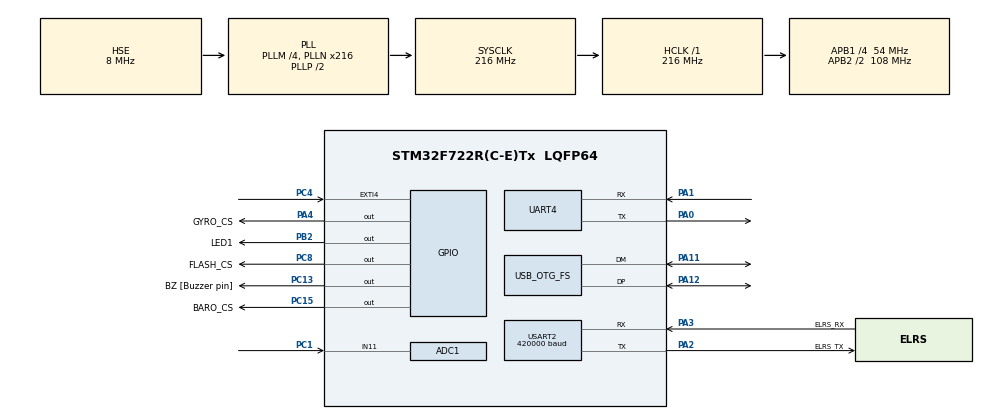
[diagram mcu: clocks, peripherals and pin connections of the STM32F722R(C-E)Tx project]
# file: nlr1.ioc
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ADC1.Channel-0\#ChannelRegularConversion=ADC_CHANNEL_11
ADC1.NbrOfConversionFlag=1
ADC1.Rank-0\#ChannelRegularConversion=1
ADC1.SamplingTime-0\#ChannelRegularConversion=ADC_SAMPLETIME_3CYCLES
ADC1.master=1
CORTEX_M7.default_mode_Activation=1
Dma.Request0=UART4_RX
Dma.Request1=USART2_RX
Dma.UART4_RX.0.Direction=DMA_PERIPH_TO_MEMORY
Dma.UART4_RX.0.FIFOMode=DMA_FIFOMODE_DISABLE
Dma.UART4_RX.0.Instance=DMA1_Stream2
Dma.UART4_RX.0.MemDataAlignment=DMA_MDATAALIGN_BYTE
Dma.UART4_RX.0.MemInc=DMA_MINC_ENABLE
Dma.UART4_RX.0.Mode=DMA_NORMAL
Dma.UART4_RX.0.PeriphDataAlignment=DMA_PDATAALIGN_BYTE
Dma.UART4_RX.0.PeriphInc=DMA_PINC_DISABLE
Dma.UART4_RX.0.Priority=DMA_PRIORITY_LOW
Dma.USART2_RX.1.Direction=DMA_PERIPH_TO_MEMORY
Dma.USART2_RX.1.FIFOMode=DMA_FIFOMODE_DISABLE
Dma.USART2_RX.1.Instance=DMA1_Stream5
Dma.USART2_RX.1.MemDataAlignment=DMA_MDATAALIGN_BYTE
Dma.USART2_RX.1.MemInc=DMA_MINC_ENABLE
Dma.USART2_RX.1.Mode=DMA_NORMAL
Dma.USART2_RX.1.PeriphDataAlignment=DMA_PDATAALIGN_BYTE
Dma.USART2_RX.1.PeriphInc=DMA_PINC_DISABLE
Dma.USART2_RX.1.Priority=DMA_PRIORITY_LOW
Mcu.Family=STM32F7
Mcu.Name=STM32F722R(C-E)Tx
Mcu.Package=LQFP64
NVIC.DMA1_Stream2_IRQn=true\:0\:0\:false\:false\:true\:false\:true\:true
NVIC.DMA1_Stream5_IRQn=true\:0\:0\:false\:false\:true\:false\:true\:true
NVIC.OTG_FS_IRQn=true\:0\:0\:false\:false\:true\:false\:true\:true
NVIC.PriorityGroup=NVIC_PRIORITYGROUP_4
NVIC.UART4_IRQn=true\:0\:0\:false\:false\:true\:true\:true\:true
NVIC.USART2_IRQn=true\:0\:0\:false\:false\:true\:true\:true\:true
PA0-WKUP.Mode=Asynchronous
PA0-WKUP.Signal=UART4_TX
PA1.Mode=Asynchronous
PA1.Signal=UART4_RX
PA10.Signal=USART1_RX
PA11.Mode=Device_Only
PA11.Signal=USB_OTG_FS_DM
PA12.Mode=Device_Only
PA12.Signal=USB_OTG_FS_DP
PA13.Mode=Serial_Wire
PA13.Signal=SYS_JTMS-SWDIO
PA14.Mode=Serial_Wire
PA14.Signal=SYS_JTCK-SWCLK
PA2.GPIO_Label=ELRS_TX
PA2.Mode=Asynchronous
PA2.Signal=USART2_TX
PA3.GPIO_Label=ELRS_RX
PA3.Mode=Asynchronous
PA3.Signal=USART2_RX
PA4.GPIO_Label=GYRO_CS
PA4.Signal=GPIO_Output
PA5.Signal=SPI1_SCK
PA6.Signal=SPI1_MISO
PA7.Signal=SPI1_MOSI
PA9.Signal=USART1_TX
PB10.Signal=I2C2_SCL
PB11.Signal=I2C2_SDA
PB2.GPIO_Label=LED1
PB2.Signal=GPIO_Output
PB3.Signal=SPI3_SCK
PB4.Signal=SPI3_MISO
PB5.Signal=SPI3_MOSI
PC1.Signal=ADCx_IN11
PC10.Signal=USART3_TX
PC11.Signal=USART3_RX
PC12.Signal=UART5_TX
PC13.GPIO_Label=BZ [Buzzer pin]
PC13.GPIO_Speed=GPIO_SPEED_FREQ_LOW
PC13.PinState=GPIO_PIN_RESET
PC13.Signal=GPIO_Output
PC15-OSC32_OUT.GPIO_Label=BARO_CS
PC15-OSC32_OUT.Signal=GPIO_Output
PC4.Signal=GPXTI4
PC8.GPIO_Label=FLASH_CS
PC8.Signal=GPIO_Output
PD2.Signal=UART5_RX
PH0-OSC_IN.Mode=HSE-External-Oscillator
PH0-OSC_IN.Signal=RCC_OSC_IN
PH1-OSC_OUT.Mode=HSE-External-Oscillator
PH1-OSC_OUT.Signal=RCC_OSC_OUT
ProjectManager.HeapSize=0x1000
ProjectManager.StackSize=0x1000
ProjectManager.TargetToolchain=STM32CubeIDE
RCC.AHBFreq_Value=216000000
RCC.APB1CLKDivider=RCC_HCLK_DIV4
RCC.APB1Freq_Value=54000000
RCC.APB1TimFreq_Value=108000000
RCC.APB2CLKDivider=RCC_HCLK_DIV2
RCC.APB2Freq_Value=108000000
RCC.APB2TimFreq_Value=216000000
RCC.CortexFreq_Value=216000000
RCC.HCLKFreq_Value=216000000
RCC.HSE_VALUE=8000000
RCC.HSI_VALUE=16000000
RCC.LSE_VALUE=32768
RCC.PLLM=4
RCC.PLLN=216
RCC.PLLQ=9
RCC.SYSCLKFreq_VALUE=216000000
RCC.SYSCLKSource=RCC_SYSCLKSOURCE_PLLCLK
RCC.USBFreq_Value=48000000
RCC.VCOOutputFreq_Value=432000000
SH.ADCx_IN11.0=ADC1_IN11,IN11
USART2.BaudRate=420000
USART2.VirtualMode-Asynchronous=VM_ASYNC
USB_DEVICE.CLASS_NAME_FS=CDC
USB_DEVICE.VirtualMode-CDC_FS=Cdc
USB_DEVICE.VirtualModeFS=Cdc_FS
USB_OTG_FS.VirtualMode=Device_Only
VP_USB_DEVICE_VS_USB_DEVICE_CDC_FS.Mode=CDC_FS
board=custom

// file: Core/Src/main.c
/* USER CODE BEGIN Header */
/**
  ******************************************************************************
  * @file           : main.c
  * @brief          : Main program body
  ******************************************************************************
  * @attention
  *
  * Copyright (c) 2026 STMicroelectronics.
  * All rights reserved.
  *
  * This software is licensed under terms that can be found in the LICENSE file
  * in the root directory of this software component.
  * If no LICENSE file comes with this software, it is provided AS-IS.
  *
  ******************************************************************************
  */
/* USER CODE END Header */
#include "main.h"
#include "usb_device.h"

/* USER CODE BEGIN Includes */
#include "usbd_cdc_if.h"
#include "radio/protocol.h"
/* USER CODE END Includes */

ADC_HandleTypeDef hadc1;

UART_HandleTypeDef huart4;
UART_HandleTypeDef huart2;
DMA_HandleTypeDef hdma_uart4_rx;
DMA_HandleTypeDef hdma_usart2_rx;

void SystemClock_Config(void);
static void MPU_Config(void);
static void MX_GPIO_Init(void);
static void MX_DMA_Init(void);
static void MX_ADC1_Init(void);
static void MX_USART2_UART_Init(void);
static void MX_UART4_Init(void);

int main(void)
{

  /* MPU Configuration--------------------------------------------------------*/
  MPU_Config();

  /* MCU Configuration--------------------------------------------------------*/

  /* Reset of all peripherals, Initializes the Flash interface and the Systick. */
  HAL_Init();

  /* Configure the system clock */
  SystemClock_Config();

  /* Initialize all configured peripherals */
  MX_GPIO_Init();
  MX_DMA_Init();
  MX_ADC1_Init();
  MX_USB_DEVICE_Init();
  MX_USART2_UART_Init();
  MX_UART4_Init();
  /* USER CODE BEGIN 2 */
  Protocol_Init();
  /* USER CODE END 2 */

  /* Infinite loop */
  while (1)
  {
	  Protocol_Task();
  }
}

void SystemClock_Config(void)
{
  RCC_OscInitTypeDef RCC_OscInitStruct = {0};
  RCC_ClkInitTypeDef RCC_ClkInitStruct = {0};

  /** Configure the main internal regulator output voltage
  */
  __HAL_RCC_PWR_CLK_ENABLE();
  __HAL_PWR_VOLTAGESCALING_CONFIG(PWR_REGULATOR_VOLTAGE_SCALE1);

  /** Initializes the RCC Oscillators according to the specified parameters
  * in the RCC_OscInitTypeDef structure.
  */
  RCC_OscInitStruct.OscillatorType = RCC_OSCILLATORTYPE_HSE;
  RCC_OscInitStruct.HSEState = RCC_HSE_ON;
  RCC_OscInitStruct.PLL.PLLState = RCC_PLL_ON;
  RCC_OscInitStruct.PLL.PLLSource = RCC_PLLSOURCE_HSE;
  RCC_OscInitStruct.PLL.PLLM = 4;
  RCC_OscInitStruct.PLL.PLLN = 216;
  RCC_OscInitStruct.PLL.PLLP = RCC_PLLP_DIV2;
  RCC_OscInitStruct.PLL.PLLQ = 9;
  if (HAL_RCC_OscConfig(&RCC_OscInitStruct) != HAL_OK)
  {
    Error_Handler();
  }

  /** Activate the Over-Drive mode
  */
  if (HAL_PWREx_EnableOverDrive() != HAL_OK)
  {
    Error_Handler();
  }

  /** Initializes the CPU, AHB and APB buses clocks
  */
  RCC_ClkInitStruct.ClockType = RCC_CLOCKTYPE_HCLK|RCC_CLOCKTYPE_SYSCLK
                              |RCC_CLOCKTYPE_PCLK1|RCC_CLOCKTYPE_PCLK2;
  RCC_ClkInitStruct.SYSCLKSource = RCC_SYSCLKSOURCE_PLLCLK;
  RCC_ClkInitStruct.AHBCLKDivider = RCC_SYSCLK_DIV1;
  RCC_ClkInitStruct.APB1CLKDivider = RCC_HCLK_DIV4;
  RCC_ClkInitStruct.APB2CLKDivider = RCC_HCLK_DIV2;

  if (HAL_RCC_ClockConfig(&RCC_ClkInitStruct, FLASH_LATENCY_7) != HAL_OK)
  {
    Error_Handler();
  }
}

static void MX_ADC1_Init(void)
{

  ADC_ChannelConfTypeDef sConfig = {0};

  /** Configure the global features of the ADC (Clock, Resolution, Data Alignment and number of conversion)
  */
  hadc1.Instance = ADC1;
  hadc1.Init.ClockPrescaler = ADC_CLOCK_SYNC_PCLK_DIV4;
  hadc1.Init.Resolution = ADC_RESOLUTION_12B;
  hadc1.Init.ScanConvMode = ADC_SCAN_DISABLE;
  hadc1.Init.ContinuousConvMode = DISABLE;
  hadc1.Init.DiscontinuousConvMode = DISABLE;
  hadc1.Init.ExternalTrigConvEdge = ADC_EXTERNALTRIGCONVEDGE_NONE;
  hadc1.Init.ExternalTrigConv = ADC_SOFTWARE_START;
  hadc1.Init.DataAlign = ADC_DATAALIGN_RIGHT;
  hadc1.Init.NbrOfConversion = 1;
  hadc1.Init.DMAContinuousRequests = DISABLE;
  hadc1.Init.EOCSelection = ADC_EOC_SINGLE_CONV;
  if (HAL_ADC_Init(&hadc1) != HAL_OK)
  {
    Error_Handler();
  }

  /** Configure for the selected ADC regular channel its corresponding rank in the sequencer and its sample time.
  */
  sConfig.Channel = ADC_CHANNEL_11;
  sConfig.Rank = ADC_REGULAR_RANK_1;
  sConfig.SamplingTime = ADC_SAMPLETIME_3CYCLES;
  if (HAL_ADC_ConfigChannel(&hadc1, &sConfig) != HAL_OK)
  {
    Error_Handler();
  }

}

static void MX_UART4_Init(void)
{

  huart4.Instance = UART4;
  huart4.Init.BaudRate = 115200;
  huart4.Init.WordLength = UART_WORDLENGTH_8B;
  huart4.Init.StopBits = UART_STOPBITS_1;
  huart4.Init.Parity = UART_PARITY_NONE;
  huart4.Init.Mode = UART_MODE_TX_RX;
  huart4.Init.HwFlowCtl = UART_HWCONTROL_NONE;
  huart4.Init.OverSampling = UART_OVERSAMPLING_16;
  huart4.Init.OneBitSampling = UART_ONE_BIT_SAMPLE_DISABLE;
  huart4.AdvancedInit.AdvFeatureInit = UART_ADVFEATURE_NO_INIT;
  if (HAL_UART_Init(&huart4) != HAL_OK)
  {
    Error_Handler();
  }

}

static void MX_USART2_UART_Init(void)
{

  huart2.Instance = USART2;
  huart2.Init.BaudRate = 9600;
  huart2.Init.WordLength = UART_WORDLENGTH_8B;
  huart2.Init.StopBits = UART_STOPBITS_1;
  huart2.Init.Parity = UART_PARITY_NONE;
  huart2.Init.Mode = UART_MODE_TX_RX;
  huart2.Init.HwFlowCtl = UART_HWCONTROL_NONE;
  huart2.Init.OverSampling = UART_OVERSAMPLING_16;
  huart2.Init.OneBitSampling = UART_ONE_BIT_SAMPLE_DISABLE;
  huart2.AdvancedInit.AdvFeatureInit = UART_ADVFEATURE_NO_INIT;
  if (HAL_UART_Init(&huart2) != HAL_OK)
  {
    Error_Handler();
  }

}

static void MX_DMA_Init(void)
{

  /* DMA controller clock enable */
  __HAL_RCC_DMA1_CLK_ENABLE();

  /* DMA interrupt init */
  /* DMA1_Stream2_IRQn interrupt configuration */
  HAL_NVIC_SetPriority(DMA1_Stream2_IRQn, 0, 0);
  HAL_NVIC_EnableIRQ(DMA1_Stream2_IRQn);
  /* DMA1_Stream5_IRQn interrupt configuration */
  HAL_NVIC_SetPriority(DMA1_Stream5_IRQn, 0, 0);
  HAL_NVIC_EnableIRQ(DMA1_Stream5_IRQn);

}

static void MX_GPIO_Init(void)
{
  GPIO_InitTypeDef GPIO_InitStruct = {0};

  /* GPIO Ports Clock Enable */
  __HAL_RCC_GPIOC_CLK_ENABLE();
  __HAL_RCC_GPIOH_CLK_ENABLE();
  __HAL_RCC_GPIOA_CLK_ENABLE();
  __HAL_RCC_GPIOB_CLK_ENABLE();
  __HAL_RCC_GPIOD_CLK_ENABLE();

  /*Configure GPIO pin Output Level */
  HAL_GPIO_WritePin(GPIOC, BZ_Pin|BARO_CS_Pin|FLASH_CS_Pin, GPIO_PIN_RESET);

  /*Configure GPIO pin Output Level */
  HAL_GPIO_WritePin(GYRO_CS_GPIO_Port, GYRO_CS_Pin, GPIO_PIN_RESET);

  /*Configure GPIO pin Output Level */
  HAL_GPIO_WritePin(LED1_GPIO_Port, LED1_Pin, GPIO_PIN_RESET);

  /*Configure GPIO pins : BZ_Pin BARO_CS_Pin FLASH_CS_Pin */
  GPIO_InitStruct.Pin = BZ_Pin|BARO_CS_Pin|FLASH_CS_Pin;
  GPIO_InitStruct.Mode = GPIO_MODE_OUTPUT_PP;
  GPIO_InitStruct.Pull = GPIO_NOPULL;
  GPIO_InitStruct.Speed = GPIO_SPEED_FREQ_LOW;
  HAL_GPIO_Init(GPIOC, &GPIO_InitStruct);

  /*Configure GPIO pin : GYRO_CS_Pin */
  GPIO_InitStruct.Pin = GYRO_CS_Pin;
  GPIO_InitStruct.Mode = GPIO_MODE_OUTPUT_PP;
  GPIO_InitStruct.Pull = GPIO_NOPULL;
  GPIO_InitStruct.Speed = GPIO_SPEED_FREQ_LOW;
  HAL_GPIO_Init(GYRO_CS_GPIO_Port, &GPIO_InitStruct);

  /*Configure GPIO pins : PA5 PA6 PA7 */
  GPIO_InitStruct.Pin = GPIO_PIN_5|GPIO_PIN_6|GPIO_PIN_7;
  GPIO_InitStruct.Mode = GPIO_MODE_AF_PP;
  GPIO_InitStruct.Pull = GPIO_NOPULL;
  GPIO_InitStruct.Speed = GPIO_SPEED_FREQ_VERY_HIGH;
  GPIO_InitStruct.Alternate = GPIO_AF5_SPI1;
  HAL_GPIO_Init(GPIOA, &GPIO_InitStruct);

  /*Configure GPIO pin : PC4 */
  GPIO_InitStruct.Pin = GPIO_PIN_4;
  GPIO_InitStruct.Mode = GPIO_MODE_IT_RISING;
  GPIO_InitStruct.Pull = GPIO_NOPULL;
  HAL_GPIO_Init(GPIOC, &GPIO_InitStruct);

  /*Configure GPIO pin : LED1_Pin */
  GPIO_InitStruct.Pin = LED1_Pin;
  GPIO_InitStruct.Mode = GPIO_MODE_OUTPUT_PP;
  GPIO_InitStruct.Pull = GPIO_NOPULL;
  GPIO_InitStruct.Speed = GPIO_SPEED_FREQ_LOW;
  HAL_GPIO_Init(LED1_GPIO_Port, &GPIO_InitStruct);

  /*Configure GPIO pins : PB10 PB11 */
  GPIO_InitStruct.Pin = GPIO_PIN_10|GPIO_PIN_11;
  GPIO_InitStruct.Mode = GPIO_MODE_AF_OD;
  GPIO_InitStruct.Pull = GPIO_NOPULL;
  GPIO_InitStruct.Speed = GPIO_SPEED_FREQ_VERY_HIGH;
  GPIO_InitStruct.Alternate = GPIO_AF4_I2C2;
  HAL_GPIO_Init(GPIOB, &GPIO_InitStruct);

  /*Configure GPIO pins : PA9 PA10 */
  GPIO_InitStruct.Pin = GPIO_PIN_9|GPIO_PIN_10;
  GPIO_InitStruct.Mode = GPIO_MODE_AF_PP;
  GPIO_InitStruct.Pull = GPIO_NOPULL;
  GPIO_InitStruct.Speed = GPIO_SPEED_FREQ_VERY_HIGH;
  GPIO_InitStruct.Alternate = GPIO_AF7_USART1;
  HAL_GPIO_Init(GPIOA, &GPIO_InitStruct);

  /*Configure GPIO pins : PC10 PC11 */
  GPIO_InitStruct.Pin = GPIO_PIN_10|GPIO_PIN_11;
  GPIO_InitStruct.Mode = GPIO_MODE_AF_PP;
  GPIO_InitStruct.Pull = GPIO_NOPULL;
  GPIO_InitStruct.Speed = GPIO_SPEED_FREQ_VERY_HIGH;
  GPIO_InitStruct.Alternate = GPIO_AF7_USART3;
  HAL_GPIO_Init(GPIOC, &GPIO_InitStruct);

  /*Configure GPIO pin : PC12 */
  GPIO_InitStruct.Pin = GPIO_PIN_12;
  GPIO_InitStruct.Mode = GPIO_MODE_AF_PP;
  GPIO_InitStruct.Pull = GPIO_NOPULL;
  GPIO_InitStruct.Speed = GPIO_SPEED_FREQ_VERY_HIGH;
  GPIO_InitStruct.Alternate = GPIO_AF8_UART5;
  HAL_GPIO_Init(GPIOC, &GPIO_InitStruct);

  /*Configure GPIO pin : PD2 */
  GPIO_InitStruct.Pin = GPIO_PIN_2;
  GPIO_InitStruct.Mode = GPIO_MODE_AF_PP;
  GPIO_InitStruct.Pull = GPIO_NOPULL;
  GPIO_InitStruct.Speed = GPIO_SPEED_FREQ_VERY_HIGH;
  GPIO_InitStruct.Alternate = GPIO_AF8_UART5;
  HAL_GPIO_Init(GPIOD, &GPIO_InitStruct);

  /*Configure GPIO pins : PB3 PB4 PB5 */
  GPIO_InitStruct.Pin = GPIO_PIN_3|GPIO_PIN_4|GPIO_PIN_5;
  GPIO_InitStruct.Mode = GPIO_MODE_AF_PP;
  GPIO_InitStruct.Pull = GPIO_NOPULL;
  GPIO_InitStruct.Speed = GPIO_SPEED_FREQ_VERY_HIGH;
  GPIO_InitStruct.Alternate = GPIO_AF6_SPI3;
  HAL_GPIO_Init(GPIOB, &GPIO_InitStruct);

}

 /* MPU Configuration */

void MPU_Config(void)
{
  MPU_Region_InitTypeDef MPU_InitStruct = {0};

  /* Disables the MPU */
  HAL_MPU_Disable();

  /** Initializes and configures the Region and the memory to be protected
  */
  MPU_InitStruct.Enable = MPU_REGION_ENABLE;
  MPU_InitStruct.Number = MPU_REGION_NUMBER0;
  MPU_InitStruct.BaseAddress = 0x0;
  MPU_InitStruct.Size = MPU_REGION_SIZE_4GB;
  MPU_InitStruct.SubRegionDisable = 0x87;
  MPU_InitStruct.TypeExtField = MPU_TEX_LEVEL0;
  MPU_InitStruct.AccessPermission = MPU_REGION_NO_ACCESS;
  MPU_InitStruct.DisableExec = MPU_INSTRUCTION_ACCESS_DISABLE;
  MPU_InitStruct.IsShareable = MPU_ACCESS_SHAREABLE;
  MPU_InitStruct.IsCacheable = MPU_ACCESS_NOT_CACHEABLE;
  MPU_InitStruct.IsBufferable = MPU_ACCESS_NOT_BUFFERABLE;

  HAL_MPU_ConfigRegion(&MPU_InitStruct);
  /* Enables the MPU */
  HAL_MPU_Enable(MPU_PRIVILEGED_DEFAULT);

}

void Error_Handler(void)
{
  __disable_irq();
  while (1)
  {
  }
}
